# S6E2DHxJ register map
Vendor: Cypress; File version: 2.1
CPU: CM4 r0p1, little endian, MPU, FPU, 4 interrupt priority bits
Registers are 32-bit, read-write, reset 0x0 unless marked. A register's access mark holds for its fields unless they carry their own. Offsets are from the block's base; [hi:lo] are bit positions; {n}, {i} and the like mark numbered series.

## GPIO
Base 0x4006F000
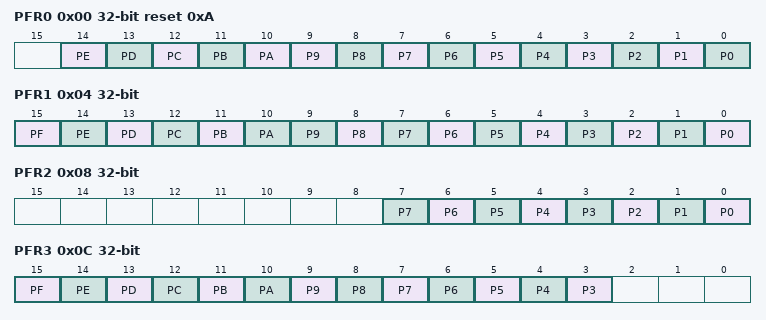
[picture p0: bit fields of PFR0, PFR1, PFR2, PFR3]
0x00 PFR0 reset 0xA — Port Function Setting Register 0 [BHW]
  [14] PE — Bit14 of PFR0
  [13] PD — Bit13 of PFR0
  [12] PC — Bit12 of PFR0
  [11] PB — Bit11 of PFR0
  [10] PA — Bit10 of PFR0
  [n] P{n} (n=0..9) — Bit{n} of PFR0
0x04 PFR1 — Port Function Setting Register 1 [BHW]
  [15] PF — Bit15 of PFR1
  [14] PE — Bit14 of PFR1
  [13] PD — Bit13 of PFR1
  [12] PC — Bit12 of PFR1
  [11] PB — Bit11 of PFR1
  [10] PA — Bit10 of PFR1
  [n] P{n} (n=0..9) — Bit{n} of PFR1
0x08 PFR2 — Port Function Setting Register 2 [BHW]
  [n] P{n} (n=0..7) — Bit{n} of PFR2
0x0C PFR3 — Port Function Setting Register 3 [BHW]
  [15] PF — Bit15 of PFR3
  [14] PE — Bit14 of PFR3
  [13] PD — Bit13 of PFR3
  [12] PC — Bit12 of PFR3
  [11] PB — Bit11 of PFR3
  [10] PA — Bit10 of PFR3
  [n] P{n} (n=3..9) — Bit{n} of PFR3
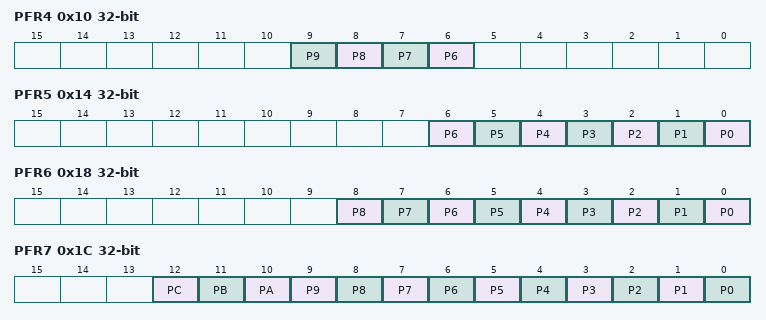
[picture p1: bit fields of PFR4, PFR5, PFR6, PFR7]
0x10 PFR4 — Port Function Setting Register 4 [BHW]
  [n] P{n} (n=6..9) — Bit{n} of PFR4
0x14 PFR5 — Port Function Setting Register 5 [BHW]
  [n] P{n} (n=0..6) — Bit{n} of PFR5
0x18 PFR6 — Port Function Setting Register 6 [BHW]
  [n] P{n} (n=0..8) — Bit{n} of PFR6
0x1C PFR7 — Port Function Setting Register 7 [BHW]
  [12] PC — Bit12 of PFR7
  [11] PB — Bit11 of PFR7
  [10] PA — Bit10 of PFR7
  [n] P{n} (n=0..9) — Bit{n} of PFR7
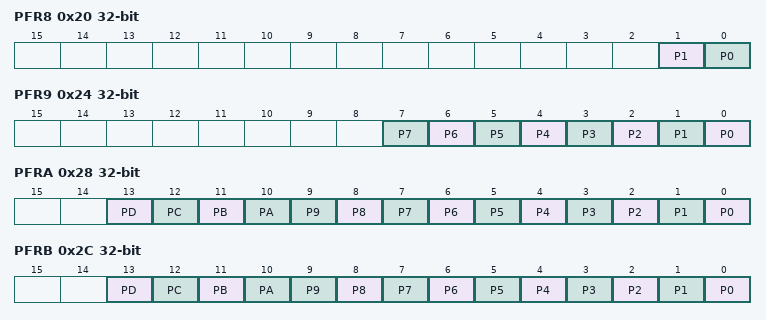
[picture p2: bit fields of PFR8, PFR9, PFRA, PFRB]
0x20 PFR8 — Port Function Setting Register 8 [BHW]
  [1] P1 — Bit1 of PFR8
  [0] P0 — Bit0 of PFR8
0x24 PFR9 — Port Function Setting Register 9 [BHW]
  [n] P{n} (n=0..7) — Bit{n} of PFR9
0x28 PFRA — Port Function Setting Register A [BHW]
  [13] PD — Bit13 of PFRA
  [12] PC — Bit12 of PFRA
  [11] PB — Bit11 of PFRA
  [10] PA — Bit10 of PFRA
  [n] P{n} (n=0..9) — Bit{n} of PFRA
0x2C PFRB — Port Function Setting Register B [BHW]
  [13] PD — Bit13 of PFRB
  [12] PC — Bit12 of PFRB
  [11] PB — Bit11 of PFRB
  [10] PA — Bit10 of PFRB
  [n] P{n} (n=0..9) — Bit{n} of PFRB
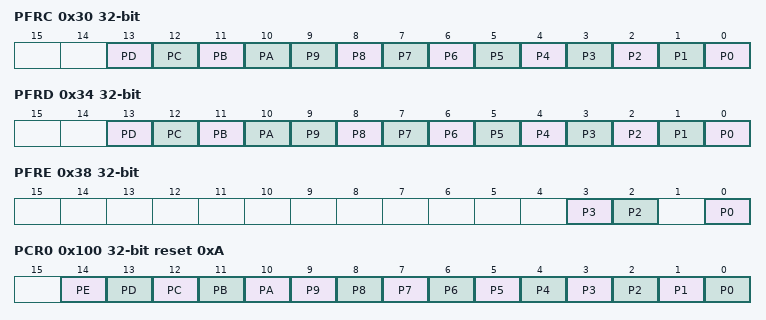
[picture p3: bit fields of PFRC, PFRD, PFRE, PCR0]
0x30 PFRC — Port Function Setting Register C [BHW]
  [13] PD — Bit13 of PFRC
  [12] PC — Bit12 of PFRC
  [11] PB — Bit11 of PFRC
  [10] PA — Bit10 of PFRC
  [n] P{n} (n=0..9) — Bit{n} of PFRC
0x34 PFRD — Port Function Setting Register D [BHW]
  [13] PD — Bit13 of PFRD
  [12] PC — Bit12 of PFRD
  [11] PB — Bit11 of PFRD
  [10] PA — Bit10 of PFRD
  [n] P{n} (n=0..9) — Bit{n} of PFRD
0x38 PFRE — Port Function Setting Register E [BHW]
  [3] P3 — Bit3 of PFRE
  [2] P2 — Bit2 of PFRE
  [0] P0 — Bit0 of PFRE
0x3C PFRF reset not defined — Port Function Setting Register F [BHW]
0x100 PCR0 reset 0xA — Pull-up Setting Register 0 [BHW]
  [14] PE — Bit14 of PCR0
  [13] PD — Bit13 of PCR0
  [12] PC — Bit12 of PCR0
  [11] PB — Bit11 of PCR0
  [10] PA — Bit10 of PCR0
  [n] P{n} (n=0..9) — Bit{n} of PCR0
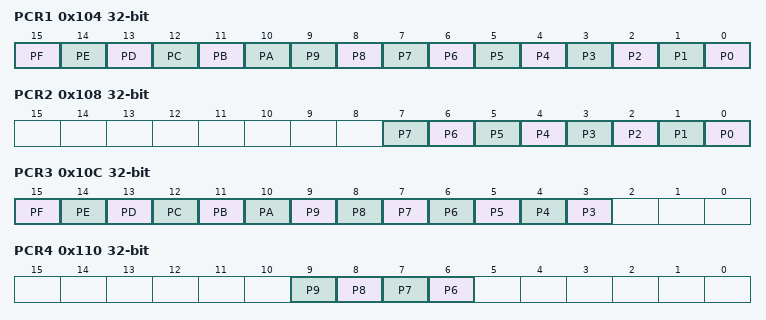
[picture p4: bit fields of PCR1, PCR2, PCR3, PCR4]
0x104 PCR1 — Pull-up Setting Register 1 [BHW]
  [15] PF — Bit15 of PCR1
  [14] PE — Bit14 of PCR1
  [13] PD — Bit13 of PCR1
  [12] PC — Bit12 of PCR1
  [11] PB — Bit11 of PCR1
  [10] PA — Bit10 of PCR1
  [n] P{n} (n=0..9) — Bit{n} of PCR1
0x108 PCR2 — Pull-up Setting Register 2 [BHW]
  [n] P{n} (n=0..7) — Bit{n} of PCR2
0x10C PCR3 — Pull-up Setting Register 3 [BHW]
  [15] PF — Bit15 of PCR3
  [14] PE — Bit14 of PCR3
  [13] PD — Bit13 of PCR3
  [12] PC — Bit12 of PCR3
  [11] PB — Bit11 of PCR3
  [10] PA — Bit10 of PCR3
  [n] P{n} (n=3..9) — Bit{n} of PCR3
0x110 PCR4 — Pull-up Setting Register 4 [BHW]
  [n] P{n} (n=6..9) — Bit{n} of PCR4
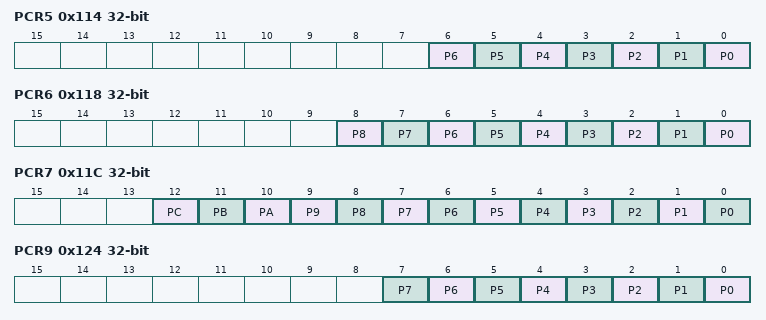
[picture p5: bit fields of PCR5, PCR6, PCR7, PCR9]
0x114 PCR5 — Pull-up Setting Register 5 [BHW]
  [n] P{n} (n=0..6) — Bit{n} of PCR5
0x118 PCR6 — Pull-up Setting Register 6 [BHW]
  [n] P{n} (n=0..8) — Bit{n} of PCR6
0x11C PCR7 — Pull-up Setting Register 7 [BHW]
  [12] PC — Bit12 of PCR7
  [11] PB — Bit11 of PCR7
  [10] PA — Bit10 of PCR7
  [n] P{n} (n=0..9) — Bit{n} of PCR7
0x124 PCR9 — Pull-up Setting Register 9 [BHW]
  [n] P{n} (n=0..7) — Bit{n} of PCR9
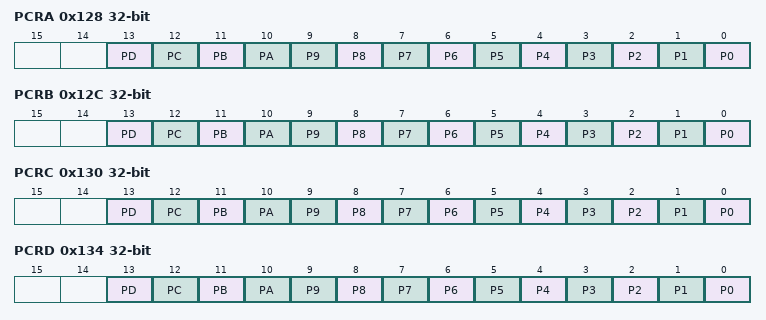
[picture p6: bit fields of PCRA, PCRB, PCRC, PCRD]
0x128 PCRA — Pull-up Setting Register A [BHW]
  [13] PD — Bit13 of PCRA
  [12] PC — Bit12 of PCRA
  [11] PB — Bit11 of PCRA
  [10] PA — Bit10 of PCRA
  [n] P{n} (n=0..9) — Bit{n} of PCRA
0x12C PCRB — Pull-up Setting Register B [BHW]
  [13] PD — Bit13 of PCRB
  [12] PC — Bit12 of PCRB
  [11] PB — Bit11 of PCRB
  [10] PA — Bit10 of PCRB
  [n] P{n} (n=0..9) — Bit{n} of PCRB
0x130 PCRC — Pull-up Setting Register C [BHW]
  [13] PD — Bit13 of PCRC
  [12] PC — Bit12 of PCRC
  [11] PB — Bit11 of PCRC
  [10] PA — Bit10 of PCRC
  [n] P{n} (n=0..9) — Bit{n} of PCRC
0x134 PCRD — Pull-up Setting Register D [BHW]
  [13] PD — Bit13 of PCRD
  [12] PC — Bit12 of PCRD
  [11] PB — Bit11 of PCRD
  [10] PA — Bit10 of PCRD
  [n] P{n} (n=0..9) — Bit{n} of PCRD
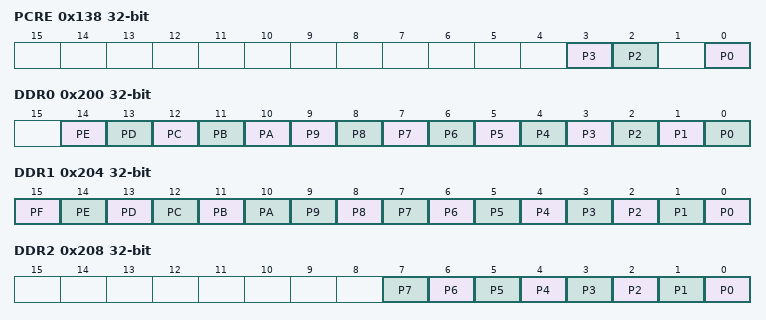
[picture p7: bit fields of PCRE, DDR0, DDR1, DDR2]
0x138 PCRE — Pull-up Setting Register E [BHW]
  [3] P3 — Bit3 of PCRE
  [2] P2 — Bit2 of PCRE
  [0] P0 — Bit0 of PCRE
0x13C PCRF reset not defined — Pull-up Setting Register F [BHW]
0x200 DDR0 — Port input/output Direction Setting Register 0 [BHW]
  [14] PE — Bit14 of DDR0
  [13] PD — Bit13 of DDR0
  [12] PC — Bit12 of DDR0
  [11] PB — Bit11 of DDR0
  [10] PA — Bit10 of DDR0
  [n] P{n} (n=0..9) — Bit{n} of DDR0
0x204 DDR1 — Port input/output Direction Setting Register 1 [BHW]
  [15] PF — Bit15 of DDR1
  [14] PE — Bit14 of DDR1
  [13] PD — Bit13 of DDR1
  [12] PC — Bit12 of DDR1
  [11] PB — Bit11 of DDR1
  [10] PA — Bit10 of DDR1
  [n] P{n} (n=0..9) — Bit{n} of DDR1
0x208 DDR2 — Port input/output Direction Setting Register 2 [BHW]
  [n] P{n} (n=0..7) — Bit{n} of DDR2
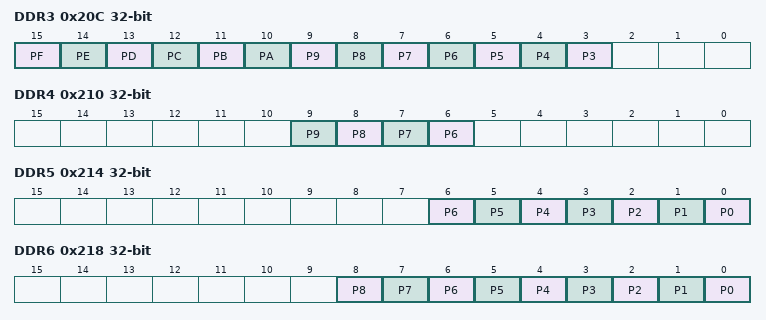
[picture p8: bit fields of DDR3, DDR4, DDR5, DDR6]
0x20C DDR3 — Port input/output Direction Setting Register 3 [BHW]
  [15] PF — Bit15 of DDR3
  [14] PE — Bit14 of DDR3
  [13] PD — Bit13 of DDR3
  [12] PC — Bit12 of DDR3
  [11] PB — Bit11 of DDR3
  [10] PA — Bit10 of DDR3
  [n] P{n} (n=3..9) — Bit{n} of DDR3
0x210 DDR4 — Port input/output Direction Setting Register 4 [BHW]
  [n] P{n} (n=6..9) — Bit{n} of DDR4
0x214 DDR5 — Port input/output Direction Setting Register 5 [BHW]
  [n] P{n} (n=0..6) — Bit{n} of DDR5
0x218 DDR6 — Port input/output Direction Setting Register 6 [BHW]
  [n] P{n} (n=0..8) — Bit{n} of DDR6
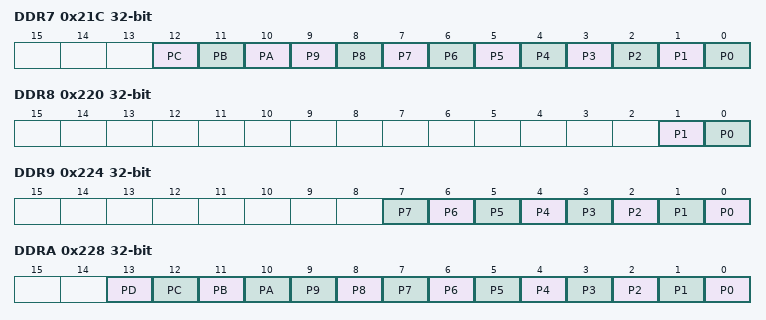
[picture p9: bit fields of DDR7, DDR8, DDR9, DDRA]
0x21C DDR7 — Port input/output Direction Setting Register 7 [BHW]
  [12] PC — Bit12 of DDR7
  [11] PB — Bit11 of DDR7
  [10] PA — Bit10 of DDR7
  [n] P{n} (n=0..9) — Bit{n} of DDR7
0x220 DDR8 — Port input/output Direction Setting Register 8 [BHW]
  [1] P1 — Bit1 of DDR8
  [0] P0 — Bit0 of DDR8
0x224 DDR9 — Port input/output Direction Setting Register 9 [BHW]
  [n] P{n} (n=0..7) — Bit{n} of DDR9
0x228 DDRA — Port input/output Direction Setting Register A [BHW]
  [13] PD — Bit13 of DDRA
  [12] PC — Bit12 of DDRA
  [11] PB — Bit11 of DDRA
  [10] PA — Bit10 of DDRA
  [n] P{n} (n=0..9) — Bit{n} of DDRA
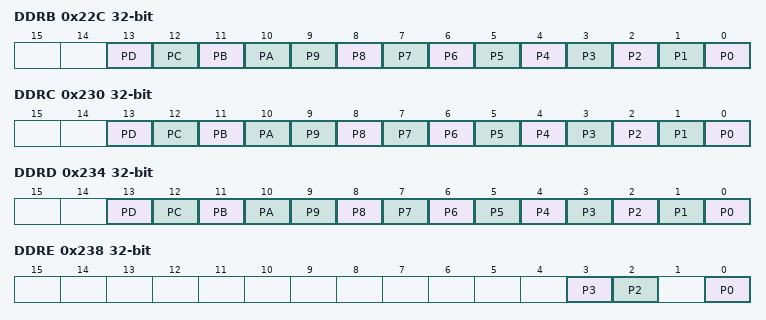
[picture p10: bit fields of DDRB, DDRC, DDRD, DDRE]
0x22C DDRB — Port input/output Direction Setting Register B [BHW]
  [13] PD — Bit13 of DDRB
  [12] PC — Bit12 of DDRB
  [11] PB — Bit11 of DDRB
  [10] PA — Bit10 of DDRB
  [n] P{n} (n=0..9) — Bit{n} of DDRB
0x230 DDRC — Port input/output Direction Setting Register C [BHW]
  [13] PD — Bit13 of DDRC
  [12] PC — Bit12 of DDRC
  [11] PB — Bit11 of DDRC
  [10] PA — Bit10 of DDRC
  [n] P{n} (n=0..9) — Bit{n} of DDRC
0x234 DDRD — Port input/output Direction Setting Register D [BHW]
  [13] PD — Bit13 of DDRD
  [12] PC — Bit12 of DDRD
  [11] PB — Bit11 of DDRD
  [10] PA — Bit10 of DDRD
  [n] P{n} (n=0..9) — Bit{n} of DDRD
0x238 DDRE — Port input/output Direction Setting Register E [BHW]
  [3] P3 — Bit3 of DDRE
  [2] P2 — Bit2 of DDRE
  [0] P0 — Bit0 of DDRE
0x23C DDRF reset not defined — Port input/output Direction Setting Register F [BHW]
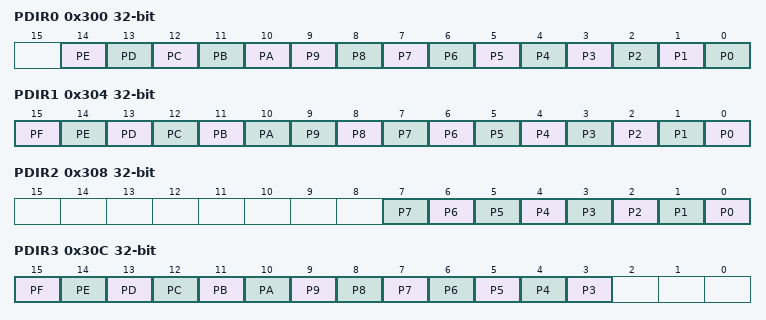
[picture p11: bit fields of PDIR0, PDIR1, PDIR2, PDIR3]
0x300 PDIR0 ro — Port Input Data Register 0 [BHW]
  [14] PE rw — Bit14 of PDIR0
  [13] PD rw — Bit13 of PDIR0
  [12] PC rw — Bit12 of PDIR0
  [11] PB rw — Bit11 of PDIR0
  [10] PA rw — Bit10 of PDIR0
  [n] P{n} rw (n=0..9) — Bit{n} of PDIR0
0x304 PDIR1 ro — Port Input Data Register 1 [BHW]
  [15] PF rw — Bit15 of PDIR1
  [14] PE rw — Bit14 of PDIR1
  [13] PD rw — Bit13 of PDIR1
  [12] PC rw — Bit12 of PDIR1
  [11] PB rw — Bit11 of PDIR1
  [10] PA rw — Bit10 of PDIR1
  [n] P{n} rw (n=0..9) — Bit{n} of PDIR1
0x308 PDIR2 ro — Port Input Data Register 2 [BHW]
  [n] P{n} rw (n=0..7) — Bit{n} of PDIR2
0x30C PDIR3 ro — Port Input Data Register 3 [BHW]
  [15] PF rw — Bit15 of PDIR3
  [14] PE rw — Bit14 of PDIR3
  [13] PD rw — Bit13 of PDIR3
  [12] PC rw — Bit12 of PDIR3
  [11] PB rw — Bit11 of PDIR3
  [10] PA rw — Bit10 of PDIR3
  [n] P{n} rw (n=3..9) — Bit{n} of PDIR3
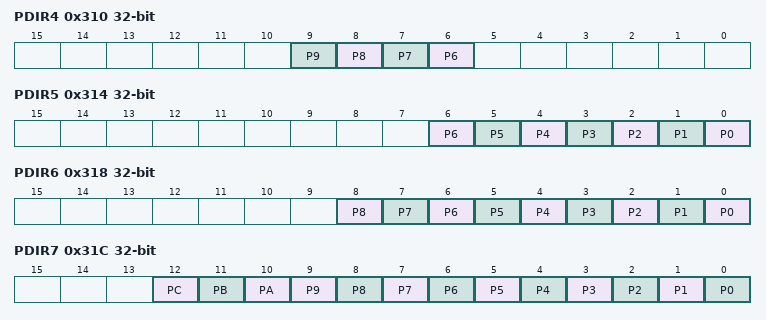
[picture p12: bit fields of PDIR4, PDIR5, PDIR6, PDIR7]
0x310 PDIR4 ro — Port Input Data Register 4 [BHW]
  [n] P{n} rw (n=6..9) — Bit{n} of PDIR4
0x314 PDIR5 ro — Port Input Data Register 5 [BHW]
  [n] P{n} rw (n=0..6) — Bit{n} of PDIR5
0x318 PDIR6 ro — Port Input Data Register 6 [BHW]
  [n] P{n} rw (n=0..8) — Bit{n} of PDIR6
0x31C PDIR7 ro — Port Input Data Register 7 [BHW]
  [12] PC rw — Bit12 of PDIR7
  [11] PB rw — Bit11 of PDIR7
  [10] PA rw — Bit10 of PDIR7
  [n] P{n} rw (n=0..9) — Bit{n} of PDIR7
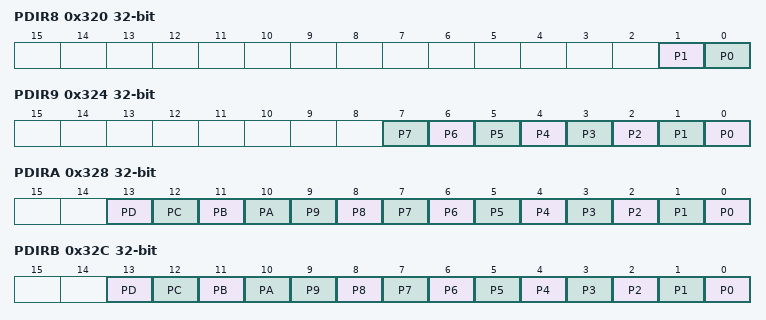
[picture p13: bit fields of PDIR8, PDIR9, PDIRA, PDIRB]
0x320 PDIR8 ro — Port Input Data Register 8 [BHW]
  [1] P1 rw — Bit1 of PDIR8
  [0] P0 rw — Bit0 of PDIR8
0x324 PDIR9 ro — Port Input Data Register 9 [BHW]
  [n] P{n} rw (n=0..7) — Bit{n} of PDIR9
0x328 PDIRA ro — Port Input Data Register A [BHW]
  [13] PD rw — Bit13 of PDIRA
  [12] PC rw — Bit12 of PDIRA
  [11] PB rw — Bit11 of PDIRA
  [10] PA rw — Bit10 of PDIRA
  [n] P{n} rw (n=0..9) — Bit{n} of PDIRA
0x32C PDIRB ro — Port Input Data Register B [BHW]
  [13] PD rw — Bit13 of PDIRB
  [12] PC rw — Bit12 of PDIRB
  [11] PB rw — Bit11 of PDIRB
  [10] PA rw — Bit10 of PDIRB
  [n] P{n} rw (n=0..9) — Bit{n} of PDIRB
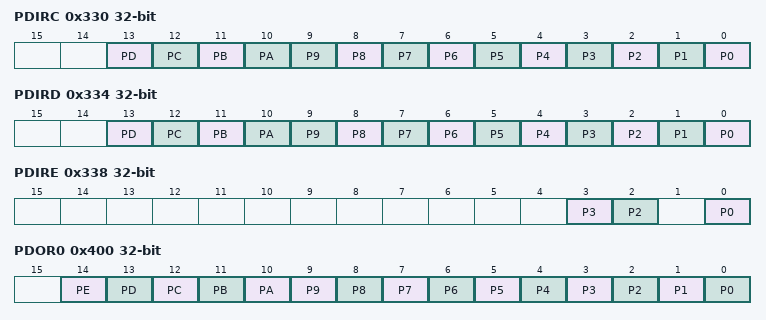
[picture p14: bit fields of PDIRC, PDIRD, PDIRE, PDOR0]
0x330 PDIRC ro — Port Input Data Register C [BHW]
  [13] PD rw — Bit13 of PDIRC
  [12] PC rw — Bit12 of PDIRC
  [11] PB rw — Bit11 of PDIRC
  [10] PA rw — Bit10 of PDIRC
  [n] P{n} rw (n=0..9) — Bit{n} of PDIRC
0x334 PDIRD ro — Port Input Data Register D [BHW]
  [13] PD rw — Bit13 of PDIRD
  [12] PC rw — Bit12 of PDIRD
  [11] PB rw — Bit11 of PDIRD
  [10] PA rw — Bit10 of PDIRD
  [n] P{n} rw (n=0..9) — Bit{n} of PDIRD
0x338 PDIRE ro — Port Input Data Register E [BHW]
  [3] P3 rw — Bit3 of PDIRE
  [2] P2 rw — Bit2 of PDIRE
  [0] P0 rw — Bit0 of PDIRE
0x33C PDIRF ro reset not defined — Port Input Data Register F [BHW]
0x400 PDOR0 — Port Output Data Register 0 [BHW]
  [14] PE — Bit14 of PDOR0
  [13] PD — Bit13 of PDOR0
  [12] PC — Bit12 of PDOR0
  [11] PB — Bit11 of PDOR0
  [10] PA — Bit10 of PDOR0
  [n] P{n} (n=0..9) — Bit{n} of PDOR0
0x404 PDOR1 — Port Output Data Register 1 [BHW]
  [15] PF — Bit15 of PDOR1
  [14] PE — Bit14 of PDOR1
  [13] PD — Bit13 of PDOR1
  [12] PC — Bit12 of PDOR1
  [11] PB — Bit11 of PDOR1
  [10] PA — Bit10 of PDOR1
  [n] P{n} (n=0..9) — Bit{n} of PDOR1
0x408 PDOR2 — Port Output Data Register 2 [BHW]
  [n] P{n} (n=0..7) — Bit{n} of PDOR2
0x40C PDOR3 — Port Output Data Register 3 [BHW]
  [15] PF — Bit15 of PDOR3
  [14] PE — Bit14 of PDOR3
  [13] PD — Bit13 of PDOR3
  [12] PC — Bit12 of PDOR3
  [11] PB — Bit11 of PDOR3
  [10] PA — Bit10 of PDOR3
  [n] P{n} (n=3..9) — Bit{n} of PDOR3
0x410 PDOR4 — Port Output Data Register 4 [BHW]
  [n] P{n} (n=6..9) — Bit{n} of PDOR4
0x414 PDOR5 — Port Output Data Register 5 [BHW]
  [n] P{n} (n=0..6) — Bit{n} of PDOR5
0x418 PDOR6 — Port Output Data Register 6 [BHW]
  [n] P{n} (n=0..8) — Bit{n} of PDOR6
0x41C PDOR7 — Port Output Data Register 7 [BHW]
  [12] PC — Bit12 of PDOR7
  [11] PB — Bit11 of PDOR7
  [10] PA — Bit10 of PDOR7
  [n] P{n} (n=0..9) — Bit{n} of PDOR7
0x420 PDOR8 — Port Output Data Register 8 [BHW]
  [1] P1 — Bit1 of PDOR8
  [0] P0 — Bit0 of PDOR8
0x424 PDOR9 — Port Output Data Register 9 [BHW]
  [n] P{n} (n=0..7) — Bit{n} of PDOR9
0x428 PDORA — Port Output Data Register A [BHW]
  [13] PD — Bit13 of PDORA
  [12] PC — Bit12 of PDORA
  [11] PB — Bit11 of PDORA
  [10] PA — Bit10 of PDORA
  [n] P{n} (n=0..9) — Bit{n} of PDORA
0x42C PDORB — Port Output Data Register B [BHW]
  [13] PD — Bit13 of PDORB
  [12] PC — Bit12 of PDORB
  [11] PB — Bit11 of PDORB
  [10] PA — Bit10 of PDORB
  [n] P{n} (n=0..9) — Bit{n} of PDORB
0x430 PDORC — Port Output Data Register C [BHW]
  [13] PD — Bit13 of PDORC
  [12] PC — Bit12 of PDORC
  [11] PB — Bit11 of PDORC
  [10] PA — Bit10 of PDORC
  [n] P{n} (n=0..9) — Bit{n} of PDORC
0x434 PDORD — Port Output Data Register D [BHW]
  [13] PD — Bit13 of PDORD
  [12] PC — Bit12 of PDORD
  [11] PB — Bit11 of PDORD
  [10] PA — Bit10 of PDORD
  [n] P{n} (n=0..9) — Bit{n} of PDORD
0x438 PDORE — Port Output Data Register E [BHW]
  [3] P3 — Bit3 of PDORE
  [2] P2 — Bit2 of PDORE
  [0] P0 — Bit0 of PDORE
0x43C PDORF reset not defined — Port Output Data Register F [BHW]
0x500 ADE reset 0xFFFFFFFF — Analog Input Setting Register [BHW]
  [23] AN23 — Analog Input Ch.23 Setting Register
  [22] AN22 — Analog Input Ch.22 Setting Register
  [21] AN21 — Analog Input Ch.21 Setting Register
  [20] AN20 — Analog Input Ch.20 Setting Register
  [19] AN19 — Analog Input Ch.19 Setting Register
  [18] AN18 — Analog Input Ch.18 Setting Register
  [17] AN17 — Analog Input Ch.17 Setting Register
  [16] AN16 — Analog Input Ch.16 Setting Register
  [15] AN15 — Analog Input Ch.15 Setting Register
  [14] AN14 — Analog Input Ch.14 Setting Register
  [13] AN13 — Analog Input Ch.13 Setting Register
  [12] AN12 — Analog Input Ch.12 Setting Register
  [11] AN11 — Analog Input Ch.11 Setting Register
  [10] AN10 — Analog Input Ch.10 Setting Register
  [9] AN09 — Analog Input Ch.9 Setting Register
  [8] AN08 — Analog Input Ch.8 Setting Register
  [7] AN07 — Analog Input Ch.7 Setting Register
  [6] AN06 — Analog Input Ch.6 Setting Register
  [5] AN05 — Analog Input Ch.5 Setting Register
  [4] AN04 — Analog Input Ch.4 Setting Register
  [3] AN03 — Analog Input Ch.3 Setting Register
  [2] AN02 — Analog Input Ch.2 Setting Register
  [1] AN01 — Analog Input Ch.1 Setting Register
  [0] AN00 — Analog Input Ch.0 Setting Register
0x580 SPSR reset 0x4 — Special Port Setting Register [BHW]
  [5] USB1C — USB (ch.1) Pin Setting bit
  [4] USB0C — USB (ch.0) Pin Setting bit
  [3:2] MAINXC — Main Clock (Oscillation) Pin Setting bits
0x600 EPFR00 reset 0x30000 — Extended Pin Function Setting Register 00 [BHW]
  [25] TRC1E — TRACED Function Select bit 1
  [24] TRC0E — TRACED Function Select bit 0
  [17] JTAGEN1S — JTAG Function Select bit 1
  [16] JTAGEN0B — JTAG Function Select bit 0
  [13] USBP1E — USB ch.1 Function Select bit 1
  [9] USBP0E — USB ch.0 Function Select bit 1
  [7:6] SUBOUTE — Sub clock divide output function select bit
  [5:4] RTCCOE — RTC clock output select bit
  [2:1] CROUTE — Internal high-speed CR Oscillation Output Function Select bit
  [0] NMIS — NMIX Function Select bit
0x604 EPFR01 — Extended Pin Function Setting Register 01 [BHW]
  [3n+22:3n+20] IC{n:02}S (n=0..3) — IC{n:02} Input Select bits
  [19:18] FRCK0S — FRCK0 Input Select bits
  [17:16] DTTI0S — DTTIX0 Input Select bits
  [12] DTTI0C — DTTIX0 Function Select bit
  [2n+1:2n] RTO{n:02}E (n=0..5) — RTO{n:02} Output Select bits
0x608 EPFR02 — Extended Pin Function Setting Register 02 [BHW]
  [3n-8:3n-10] IC{n}S (n=10..13) — IC13 Input Select bits
  [19:18] FRCK1S — FRCK1 Input Select bits
  [17:16] DTTI1S — DTTIX1 Input Select bits
  [12] DTTI1C — DTTIX1 Function Select bit
  [2n-19:2n-20] RTO{n}E (n=10..15) — RTO{n} Output Select bits
0x60C EPFR03 — Extended Pin Function Setting Register 03 [BHW]
  [3n-38:3n-40] IC{n}S (n=20..23) — IC23 Input Select bits
  [19:18] FRCK2S — FRCK2 Input Select bits
  [17:16] DTTI2S — DTTIX2 Input Select bits
  [12] DTTI2C — DTTIX2 Function Select bit
  [2n-39:2n-40] RTO{n}E (n=20..25) — RTO{n} Output Select bits
0x610 EPFR04 — Extended Pin Function Setting Register 04 [BHW]
  [29:28] TIOB3S — TIOB3 Input Select bits
  [8n+3:8n+2] TIOA{n}E (n=0..3) — TIOA{n} Output Select bits
  [25:24] TIOA3S — TIOA3 Input Select bits
  [21:20] TIOB2S — TIOB2 Input Select bits
  [13:12] TIOB1S — TIOB1 Input Select bits
  [9:8] TIOA1S — TIOA1 Input Select bits
  [6:4] TIOB0S — TIOB0 Input Select bits
0x614 EPFR05 — Extended Pin Function Setting Register 05 [BHW]
  [8n-27:8n-28] TIOB{n}S (n=4..7) — TIOB{n} Input Select bits
  [8n-29:8n-30] TIOA{n}E (n=4..7) — TIOA{n} Output Select bits
  [25:24] TIOA7S — TIOA7 Input Select bits
  [9:8] TIOA5S — TIOA5 Input Select bits
0x618 EPFR06 — Extended Pin Function Setting Register 06 [BHW]
  [2n+1:2n] EINT{n:02}S (n=0..15) — External Interrupt {n:02} Input Select bits
0x61C EPFR07 — Extended Pin Function Setting Register 07 [BHW]
  [6n+9:6n+8] SCK{n}B (n=0..3) — SCK{n} Input/Output Select bits
  [6n+7:6n+6] SOT{n}B (n=0..3) — SOT{n} Input/Output Select bits
  [6n+5:6n+4] SIN{n}S (n=0..3) — SIN{n} Input Select bits
0x620 EPFR08 — Extended Pin Function Setting Register 08 [BHW]
  [31:30] CTS5S — CTS5 Input/Output Select bits
  [29:28] RTS5E — RTS5 Input/Output Select bits
  [6n-15:6n-16] SCK{n}B (n=4..7) — SCK{n} Input/Output Select bits
  [6n-17:6n-18] SOT{n}B (n=4..7) — SOT{n} Input/Output Select bits
  [6n-19:6n-20] SIN{n}S (n=4..7) — SIN{n} Input Select bits
  [3:2] CTS4S — CTS4 Input/Output Select bits
  [1:0] RTS4E — RTS4 Input/Output Select bits
0x624 EPFR09 — Extended Pin Function Setting Register 09 [BHW]
  [31:30] CTX1E — CTX1E Output Select bits
  [29:28] CRX1S — CRX1S Input Select bits
  [27:26] CTX0E — CTX0E Output Select bits
  [25:24] CRX0S — CRX0S Input Select bits
  [23:20] ADTRG2S — ADTRG2 Input Select bits
  [19:16] ADTRG1S — ADTRG1 Input Select bits
  [15:12] ADTRG0S — ADTRG0 Input Select bits
  [11:10] QZIN1S — QZIN1S Input Select bits
  [9:8] QBIN1S — QBIN1S Input Select bits
  [7:6] QAIN1S — QAIN1S Input Select bits
  [5:4] QZIN0S — QZIN0S Input Select bits
  [3:2] QBIN0S — QBIN0S Input Select bits
  [1:0] QAIN0S — QAIN0S Input Select bits
0x628 EPFR10 — Extended Pin Function Setting Register 10 [BHW]
  [n+7] UEA{n:02}E (n=8..24) — UEA{n:02}E Output Select bit
  [14] UEAOOE — UEAOOE Output Select bit
  [n+6] UECS{n}E (n=1..7) — UECS{n}E Output Select bit
  [6] UEFLSE — UEFLSE Output Select bit
  [5] UEOEXE — UEOEXE Output Select bit
  [4] UEDQME — UEDQME Output Select bit
  [3] UEWEXE — UEWEXE Output Select bit
  [2] UECLKE — UECLKE Output Select bit
  [1] UEDTHB — UEDTHB Input/Output Select bit
  [0] UEDEFB — UEDEFB Input/Output Select bit
0x62C EPFR11 — Extended Pin Function Setting Register 11 [BHW]
  [25] UERLC — UERLC relocation select bit
  [n+9] UED{n:02}B (n=0..15) — UED{n:02}B Input/Output Select bit
  [n+1] UEA{n:02}E (n=1..7) — UEA{n:02}E Output Select bit
  [1] UECS0E — UECS0E Output Select bit
  [0] UEALEE — UEALEE Output Select bit
0x630 EPFR12 — Extended Pin Function Setting Register 12 [BHW]
  [8n-59:8n-60] TIOB{n}S (n=8..11) — TIOB{n} Input Select bits
  [8n-61:8n-62] TIOA{n}E (n=8..11) — TIOA{n} Output Select bits
  [25:24] TIOA11S — TIOA11 Input Select bits
  [9:8] TIOA9S — TIOA9 Input Select bits
0x634 EPFR13 — Extended Pin Function Setting Register 13 [BHW]
  [8n-91:8n-92] TIOB{n}S (n=12..15) — TIOB{n} Input Select bits
  [8n-93:8n-94] TIOA{n}E (n=12..15) — TIOA{n} Output Select bits
  [25:24] TIOA15S — TIOA15 Input Select bits
  [9:8] TIOA13S — TIOA13 Input Select bits
0x638 EPFR14 — Extended Pin Function Setting Register 14 [BHW]
  [29:28] E_SPLC — Input cutoff Select bit in Standby of input Pin for Ethernet-MAC
  [27] E_PSE — PPS0_PPS1 Output Select bit for Ethernet-MAC
  [26] E_CKE — E_COUT Output Select bit
  [25] E_MD1B — E_MDO1 I/O Select bit
  [24] E_MD0B — E_MDO0 I/O Select bit
  [23] E_MC1B — E_MDC1 I/O Select bit
  [22] E_MC0E — E_MDC0 Output Select bit
  [21] E_TE1E — E_TXER0_TXEN1 Output Select bit
  [20] E_TE0E — E_TXEN0 Output Select bit
  [19] E_TD1E — E_TX02_TX10/E_TX03_TX11 Output Select bit
  [18] E_TD0E — E_TX00/E_TX01 Output Select bit
  [5:4] QZIN2S — QDU-ch.2 ZIN Input Pin bits
  [3:2] QBIN2S — QDU-ch.2 BIN Input Pin bits
  [1:0] QAIN2S — QDU-ch.2 AIN Input Pin bits
0x63C EPFR15 — Extended Pin Function Setting Register 15 [BHW]
  [2n-31:2n-32] EINT{n}S (n=16..31) — External Interrupt {n} Input Select bits
0x640 EPFR16 — Extended Pin Function Setting Register 16 [BHW]
  [29] SFMPBC — MFS ch.B I2C FastMode+ Select bit
  [28] SFMPAC — MFS ch.A I2C FastMode+ Select bit
  [6n-39:6n-40] SCK{n}B (n=8..11) — SCK{n} Input/Output Select bits
  [6n-41:6n-42] SOT{n}B (n=8..11) — SOT{n} Input/Output Select bits
  [6n-43:6n-44] SIN{n}S (n=8..11) — SIN{n} Input Select bits
  [3:2] SCS7B — SCS7 Input/Output Select bits
  [1:0] SCS6B — SCS6 Select bits
0x644 EPFR17 — Extended Pin Function Setting Register 17 [BHW]
  [6n-63:6n-64] SCK{n}B (n=12..15) — SCK{n} Input/Output Select bits
  [6n-65:6n-66] SOT{n}B (n=12..15) — SOT{n} Input/Output Select bits
  [6n-67:6n-68] SIN{n}S (n=12..15) — SIN{n} Input Select bits
0x648 EPFR18 — Extended Pin Function Setting Register 18 [BHW]
  [29:28] SDWPS — S_WP input select bits
  [27:26] SDCDS — S_CD input select bits
  [2n+19:2n+18] SDDATA{n}B (n=0..3) — SDDATA{n} input/output select bits
  [17:16] SDCMDB — S_CMD input/output select bits
  [15:14] SDCLKE — S_CLK output select bits
  [9:8] QZIN3S — QDU-ch3 ZIN input select bits
  [7:6] QBIN3S — QDU-ch3 BIN input select bits
  [5:4] QAIN3S — QDU-ch3 AIN input select bits
0x64C EPFR19 reset not defined — Extended Pin Function Setting Register 19 [BHW]
0x650 EPFR20 — Extended Pin Function Setting Register 20 [BHW]
  [n-7] UED{n}B (n=16..31) — UED{n}B input/output select bit
  [8] UEDTHHB — UEDTHHB input/output select bit
  [7] UEDQM3E — UEDQM3E output select bit
  [6] UEDQM2E — UEDQM2E output select bit
  [5] UECSXE — UECSXE output select bit
  [4] UEDWEXE — UEDWEXE output select bit
  [3] UECASE — UECASE output select bit
  [2] UERASE — UERASE output select bit
  [1] UESMCEE — UESMCEE output select bit
  [0] UESMCKE — UESMCKE output select bit
0x654 EPFR21 reset not defined — Extended Pin Function Setting Register 21 [BHW]
0x658 EPFR22 reset not defined — Extended Pin Function Setting Register 22 [BHW]
0x65C EPFR23 — Extended Pin Function Setting Register 23 [BHW]
  [2n-131:2n-132] SCS{n}E (n=70..73) — SCS{n} Input Select bits
  [2n-119:2n-120] SCS{n}E (n=60..63) — SCS{n} Input Select bits
0x660 EPFR24 — Extended Pin Function Setting Register 24 [BHW]
  [27:26] I2SM4_SDO1E — I2SDO1 Output Select bits
  [25:24] I2SM4_SDI1S — I2SDI1 Input Select bits
  [23:22] I2SM4_WS1B — I2SWS1 Input/Output Select bits
  [21:20] I2SM4_SCK1B — I2SCK1 Input/Output Select bits
  [19:18] I2SM4_MCLK1E — I2SMCLK1 Output Select bits
  [17:16] I2SM4_MCLK1S — I2SMCLK1 Input Select bits
  [11:10] I2SM4_SDO0E — I2SDO0 Output Select bits
  [9:8] I2SM4_SDI0S — I2SDI0 Input Select bits
  [7:6] I2SM4_WS0B — I2SWS0 Input/Output Select bits
  [5:4] I2SM4_SCK0B — I2SCK0 Input/Output Select bits
  [3:2] I2SM4_MCLK0E — I2SMCLK0 Output Select bits
  [1:0] I2SM4_MCLK0S — I2SMCLK0 Input Select bits
0x664 EPFR25 — Extended Pin Function Setting Register 25 [BHW]
  [3:2] MCTX2E — TX2 Output Select bits
  [1:0] MCRX2S — RX2 Input Select bits
0x668 EPFR26 — Extended Pin Function Setting Register 26 [BHW]
  [2n+11:2n+10] Q_IO{n}B (n=0..3) — Q_IO{n} Input Select bits
  [2n+3:2n+2] Q_CS{n}E (n=0..3) — Q_CS{n} Input Select bits
  [1:0] Q_SCKB — Q_SCK Input Select bits
0x66C EPFR27 — Extended Pin Function Setting Register 27 [BHW]
  [31:30] HBINTXS — GE_HBINTX Input Select bits
  [29:28] HBRSTOXS — GE_HBRSTOX Input Select bits
  [27:26] HBRESETXE — GE_HBRESETX Output Select bits
  [25:24] HBWPXE — GE_HBWPX Output Select bits
  [2n+9:2n+8] HBDQ{n}B (n=0..7) — GE_HBDQ{n} Input/Output Select bits
  [7:6] HBRWDSB — GE_HBRWDS Input/Output Select bits
  [5:4] HBCSX_1E — GE_HBCSX_1 Output Select bits
  [3:2] HBCSX_0E — GE_HBCSX_0 Output Select bits
  [1:0] HBCKE — GE_HBCK Output Select bits
0x670 EPFR28 — Extended Pin Function Setting Register 28 [BHW]
  [2n+1:2n] PNL_PD{n}E (n=0..15) — PNL_PD{n} Output Select bits
0x674 EPFR29 — Extended Pin Function Setting Register 29 [BHW]
  [2n+9:2n+8] PNL_TSIG{n}E (n=5..11) — PNL_TSIG{n} Output Select bits
  [2n-31:2n-32] PNL_PD{n}E (n=16..23) — PNL_TSIG{n} Output Select bits
0x678 EPFR30 — Extended Pin Function Setting Register 30 [BHW]
  [2n+17:2n+16] PNL_TSIG{n}E (n=0..4) — PNL_TSIG{n} Output Select bits
  [11:10] PNL_LH_SYNCE — PNL_LH_SYNC Output Select bits
  [9:8] PNL_FV_SYNCE — PNL_FV_SYNC Output Select bits
  [7:6] PNL_LEE — PNL_LE Output Select bits
  [5:4] PNL_DENE — PNL_DEN Output Select bits
  [3:2] PNL_DCLKE — PNL_DCLK Output Select bits
  [1:0] PNL_PWEE — PNL_PWE Output Select bits
0x700 PZR0 — Port Pseudo Open Drain Setting Register 0 [BHW]
  [14] PE — Bit14 of PZR0
  [13] PD — Bit13 of PZR0
  [12] PC — Bit12 of PZR0
  [11] PB — Bit11 of PZR0
  [10] PA — Bit10 of PZR0
  [n] P{n} (n=0..9) — Bit{n} of PZR0
0x704 PZR1 — Port Pseudo Open Drain Setting Register 1 [BHW]
  [15] PF — Bit15 of PZR1
  [14] PE — Bit14 of PZR1
  [13] PD — Bit13 of PZR1
  [12] PC — Bit12 of PZR1
  [11] PB — Bit11 of PZR1
  [10] PA — Bit10 of PZR1
  [n] P{n} (n=0..9) — Bit{n} of PZR1
0x708 PZR2 — Port Pseudo Open Drain Setting Register 2 [BHW]
  [n] P{n} (n=0..7) — Bit{n} of PZR2
0x70C PZR3 — Port Pseudo Open Drain Setting Register 3 [BHW]
  [15] PF — Bit15 of PZR3
  [14] PE — Bit14 of PZR3
  [13] PD — Bit13 of PZR3
  [12] PC — Bit12 of PZR3
  [11] PB — Bit11 of PZR3
  [10] PA — Bit10 of PZR3
  [n] P{n} (n=3..9) — Bit{n} of PZR3
0x710 PZR4 — Port Pseudo Open Drain Setting Register 4 [BHW]
  [n] P{n} (n=6..9) — Bit{n} of PZR4
0x714 PZR5 — Port Pseudo Open Drain Setting Register 5 [BHW]
  [n] P{n} (n=0..6) — Bit{n} of PZR5
0x718 PZR6 — Port Pseudo Open Drain Setting Register 6 [BHW]
  [n] P{n} (n=0..8) — Bit{n} of PZR6
0x71C PZR7 — Port Pseudo Open Drain Setting Register 7 [BHW]
  [12] PC — Bit12 of PZR7
  [11] PB — Bit11 of PZR7
  [10] PA — Bit10 of PZR7
  [n] P{n} (n=0..9) — Bit{n} of PZR7
0x720 PZR8 — Port Pseudo Open Drain Setting Register 8 [BHW]
  [1] P1 — Bit1 of PZR8
  [0] P0 — Bit0 of PZR8
0x724 PZR9 — Port Pseudo Open Drain Setting Register 9 [BHW]
  [n] P{n} (n=0..7) — Bit{n} of PZR9
0x728 PZRA — Port Pseudo Open Drain Setting Register A [BHW]
  [13] PD — Bit13 of PZRA
  [12] PC — Bit12 of PZRA
  [11] PB — Bit11 of PZRA
  [10] PA — Bit10 of PZRA
  [n] P{n} (n=0..9) — Bit{n} of PZRA
0x72C PZRB — Port Pseudo Open Drain Setting Register B [BHW]
  [13] PD — Bit13 of PZRB
  [12] PC — Bit12 of PZRB
  [11] PB — Bit11 of PZRB
  [10] PA — Bit10 of PZRB
  [n] P{n} (n=0..9) — Bit{n} of PZRB
0x730 PZRC — Port Pseudo Open Drain Setting Register C [BHW]
  [13] PD — Bit13 of PZRC
  [12] PC — Bit12 of PZRC
  [11] PB — Bit11 of PZRC
  [10] PA — Bit10 of PZRC
  [n] P{n} (n=0..9) — Bit{n} of PZRC
0x734 PZRD — Port Pseudo Open Drain Setting Register D [BHW]
  [13] PD — Bit13 of PZRD
  [12] PC — Bit12 of PZRD
  [11] PB — Bit11 of PZRD
  [10] PA — Bit10 of PZRD
  [n] P{n} (n=0..9) — Bit{n} of PZRD
0x738 PZRE — Port Pseudo Open Drain Setting Register E [BHW]
  [3] P3 — Bit3 of PZRE
  [2] P2 — Bit2 of PZRE
  [0] P0 — Bit0 of PZRE
0x73C PZRF reset not defined — Port Pseudo Open Drain Setting Register F [BHW]
